# DECODER0_IMG_VIDEO_BUS4_MMU register map
Vendor: Texas Instruments
Peripheral module from a debugger description file (folder J7ES).
Registers are 32-bit, read-write, reset 0x0 unless marked. A register's access mark holds for its fields unless they carry their own. Offsets are as the file gives them; lines under a group give offsets from that group; [hi:lo] are bit positions; {n}, {i} and the like mark numbered series; 'fields as' and 'values as' point back to an identical list; <NAME> marks a mode.

## DECODER0_IMG_VIDEO_BUS4_MMU
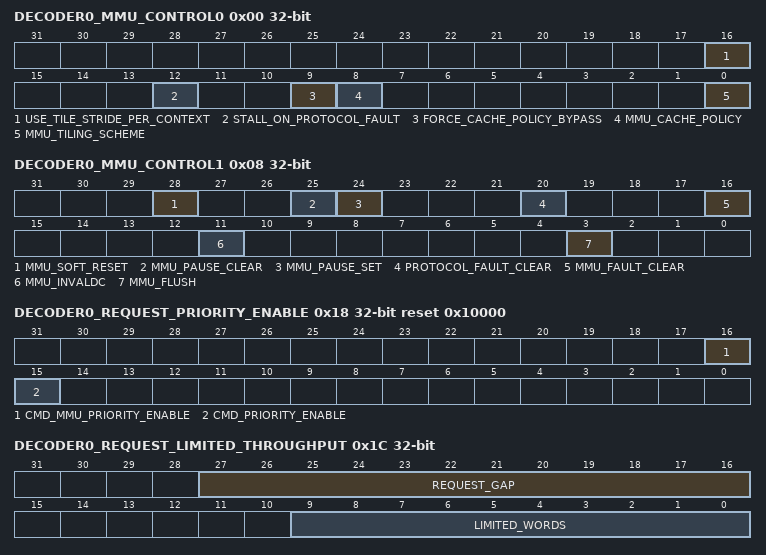
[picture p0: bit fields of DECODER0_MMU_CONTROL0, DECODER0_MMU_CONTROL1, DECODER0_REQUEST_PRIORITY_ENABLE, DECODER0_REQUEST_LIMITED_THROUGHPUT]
0x00 DECODER0_MMU_CONTROL0
  [16] USE_TILE_STRIDE_PER_CONTEXT
  [12] STALL_ON_PROTOCOL_FAULT — Debug only:Setting this bit to '1' causes any requestor with a protocol fault to stall
  [9] FORCE_CACHE_POLICY_BYPASS — Setting this bit to '1' causes all requests to external memory to have a cache policy of 0 [bypass], setting this bit to '0' passes internal cache policy to external interface
  [8] MMU_CACHE_POLICY
  [0] MMU_TILING_SCHEME — This bit controls the tiling scheme described in MMU Address Tiling section
0x08 DECODER0_MMU_CONTROL1
  [28] MMU_SOFT_RESET — Writing '1' to this bit causes all currently active or new memory requests to be discarded, so a reset of all active requestors is likely to also be required.
  [25] MMU_PAUSE_CLEAR — Writing '1' to this bit clears the pause bit, and allows new memory requests to resume.
  [24] MMU_PAUSE_SET — Writing '1' to this bit causes all new memory requests to pause [requests further down the pipeline will be allowed to complete].
  [20] PROTOCOL_FAULT_CLEAR — Writing '1' to this bit clears all bus protocol fault flags.
  [16] MMU_FAULT_CLEAR — Writing '1' to this bit clears MMU fault [either page fault or read/write fault].
  [11] MMU_INVALDC — For each 'dir_base_addr' used, writing '1' triggers invalidation[/flushing] of both the directory cache and page table cache for that 'dir_base_addr' [cached results for different 'dir_base_addr' can be invalidated/flushed independently].
  [3] MMU_FLUSH — For each 'dir_base_addr' used, writing '1' triggers a flush of the Page Table cache and registered results for that 'dir_base_addr' [cached results for different 'dir_base_addr' can be flushed independently].
0x10 DECODER0_MMU_BANK_INDEX
  [31:30] MMU_BANK_INDEX — Specify which directory base address to use for 'group override' input n [If GROUP_OVERRIDE_SIZE is 0, this register is not used, otherwise there are '2 to the power GROUP_OVERRIDE_SIZE' entries supported in this register
0x14 DECODER0_EXT_REQUEST_PRIORITY_ENABLE
  [31] EXT_CMD_PRIORITY_ENABLE — This register is only used if there are more than 16 requestors, in which case it defines the enable for requestors 16 to 47.
0x18 DECODER0_REQUEST_PRIORITY_ENABLE reset 0x10000
  [16] CMD_MMU_PRIORITY_ENABLE — MMU requests [Directory Table and Page Table reads] should normally be considered a priority on the bus infrastructure.
  [15] CMD_PRIORITY_ENABLE — Each requestor can generate a command priority signal to indicate the request should be treated as a priority in the external bus infrastructure [MMU requests are always considered to be a priority].
0x1C DECODER0_REQUEST_LIMITED_THROUGHPUT — This register controls the memory bus stalling behaviour which occurs when the 'mem_limited_throughput' input is set. The 'mem_limited_throughput' input is set by the bus fabric to indicate that the bus infrastructure is becoming saturated and that the bandwidth consumed by lower priority requests should be limited. When the 'mem_limited_throughput' input is set, for 'REQUEST_GAP' cycles all command requests into the MMU will be stalled (any requests already inside the MMU are allowed to continue as normal). Once the request gap is complete, 'LIMITED_WORDS' commands will be allowed into the MMU. When the 'mem_limited_throughput' input is cleared the counters are disabled (set to zero) and all requests proceed without limit. High priority requests (as defined by the CMD_PRIORITY_ENABLE register) are not stalled and pass unheeded. When either REQUEST_GAP or LIMITED_WORDS is set to zero the counters are disabled (set to zero) and all memory requests pass unheeded. N.B. LIMITED_WORDS threshold applies to commands, where there are typically 4 words transferred per command, so the bandwidth stalling ratio is typically closer to LIMTED_WORDS*4:REQUEST_GAP
  [27:16] REQUEST_GAP — Number of cycles all command requests are stalled for due to 'mem_limited_throughput' being set
  [9:0] LIMITED_WORDS — Number of commands which can be issued before all requests are stalled for 'REQUEST_GAP' cycles due to 'mem_limited_throughput' being set
{0x20+4i} DECODER0_MMU_DIR_BASE_ADDR_{i:02} (i=0..3)
  [31:0] MMU_DIR_BASE_ADDR — Base address in physical memory for MMU Directory n Entries.
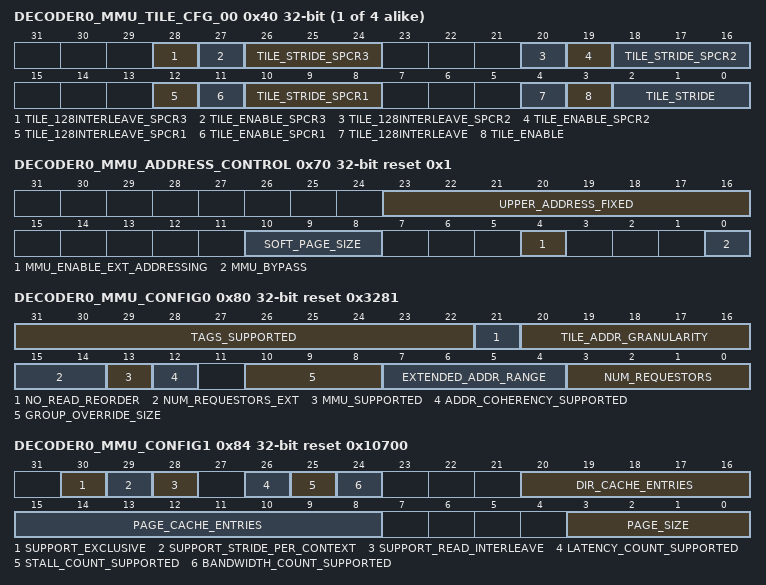
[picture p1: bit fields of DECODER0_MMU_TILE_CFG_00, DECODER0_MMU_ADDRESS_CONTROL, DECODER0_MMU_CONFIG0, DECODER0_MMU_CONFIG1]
{0x40+4i} DECODER0_MMU_TILE_CFG_{i:02} (i=0..3) — If USE_TILE_STRIDE_PER_CONTEXT is low, only the bottom byte of the register is used, and each of the four registers applies to the four regions defined by the corresponding MIN and MAX tile address ranges.If USE_TILE_STRIDE_PER_CONTEXT is high, the four bytes in a register applies to the four regions defined by the corresponding MIN and MAX tile address ranges. Then each of the four registers apply to four different contexts, where each context can use a different stride, but the MIN to MAX address range defining each region is common to all contexts (where context is the 2-bit index selected from the register).
  [28] TILE_128INTERLEAVE_SPCR3
  [27] TILE_ENABLE_SPCR3
  [26:24] TILE_STRIDE_SPCR3 — Defines the X Tile Stride for the memory address range [stride is 2 to the power of [9+tile_stride+tiling_scheme]]
  [20] TILE_128INTERLEAVE_SPCR2
  [19] TILE_ENABLE_SPCR2
  [18:16] TILE_STRIDE_SPCR2 — Defines the X Tile Stride for the memory address range [stride is 2 to the power of [9+tile_stride+tiling_scheme]]
  [12] TILE_128INTERLEAVE_SPCR1
  [11] TILE_ENABLE_SPCR1
  [10:8] TILE_STRIDE_SPCR1 — Defines the X Tile Stride for the memory address range [stride is 2 to the power of [9+tile_stride+tiling_scheme]]
  [4] TILE_128INTERLEAVE
  [3] TILE_ENABLE
  [2:0] TILE_STRIDE — Defines the X Tile Stride for the memory address range [stride is 2 to the power of [9+tile_stride+tiling_scheme]]
{0x50+4i} DECODER0_MMU_TILE_MIN_ADDR_{i:02} (i=0..3)
  [31:0] TILE_MIN_ADDR — Defines the minimum address for tiling range, in terms of the virtual address MSB's i.e.
{0x60+4i} DECODER0_MMU_TILE_MAX_ADDR_{i:02} (i=0..3)
  [31:0] TILE_MAX_ADDR — Defines the maximum address for tiling range, in terms of the virtual address MSB's i.e.
0x70 DECODER0_MMU_ADDRESS_CONTROL reset 0x1
  [23:16] UPPER_ADDRESS_FIXED — If 'EXTENDED_ADDR_RANGE' is &gt; 0, and MMU is used in bypass mode or MMU_ENABLE_EXT_ADDRESSING = '0', EXTENDED_ADDR_RANGE bits from this field will be used to define the state of the upper physical address bits [for all memory requests]
  [10:8] SOFT_PAGE_SIZE — This field selects MMU page size at run time [if this field is less than the minimum hardware configuration for PAGE_SIZE from
  [4] MMU_ENABLE_EXT_ADDRESSING
  [0] MMU_BYPASS
0x80 DECODER0_MMU_CONFIG0 ro reset 0x3281
  [31:22] TAGS_SUPPORTED — Number of outstanding bursts supported
  [21] NO_READ_REORDER — If this field is set, it indicates there is no read data re-ordering buffer [all requestors must accept read response out of order]
  [20:16] TILE_ADDR_GRANULARITY — This field indicates the granularity of the tile address range [where virtual address range is matched from
  [15:14] NUM_REQUESTORS_EXT — In MMU version 4.2 onwards, NUM_REQUESTORS_EXT*16 + NUM_REQUESTORS indicates the number of requestors the core has been configured for [before version 4.2 this field was always 0]
  [13] MMU_SUPPORTED — This field indicates if MMU page table mapping is supported [N.B.
  [12] ADDR_COHERENCY_SUPPORTED — This field indicates if address coherency checking is supported [if it is not supported requestors need to use another mechanism to gurantee reads and writes to the same address don't occur out of order]
  [10:8] GROUP_OVERRIDE_SIZE — If this field is 0, only 1 directory base address is supported [MMU_DIR_BASE_ADDR0].
  [7:4] EXTENDED_ADDR_RANGE — This field indicates the number of extended address bits [above 32] that the external memory interface uses
  [3:0] NUM_REQUESTORS — Before MMU version 4.2, this field indicates the number of requestors the core has been configured for [between 1 and 15, or a value of
0x84 DECODER0_MMU_CONFIG1 ro reset 0x10700
  [30] SUPPORT_EXCLUSIVE — Logic included to support exclusive transactions [for doing read-modify-write without another master modifying the value]
  [29] SUPPORT_STRIDE_PER_CONTEXT — Logic included to support separate tile stride per context
  [28] SUPPORT_READ_INTERLEAVE — Logic included to support interleaved read responses [violates Bus4 protocol but may occur when Bus4 to AXI bridge is used]
  [26] LATENCY_COUNT_SUPPORTED — Latency counts included
  [25] STALL_COUNT_SUPPORTED — Stall counts included
  [24] BANDWIDTH_COUNT_SUPPORTED — Bandwidth counts included
  [20:16] DIR_CACHE_ENTRIES — DIR_CACHE_ENTRIES * 128 defines the number of Directory Table entries which can be cached
  [15:8] PAGE_CACHE_ENTRIES — PAGE_CACHE_ENTRIES * 128 defines the number of Page Table entries which can be cached
  [3:0] PAGE_SIZE — Log2 MMU page size minus 12 [4kbyte page = 0, 16kbyte page = 2]
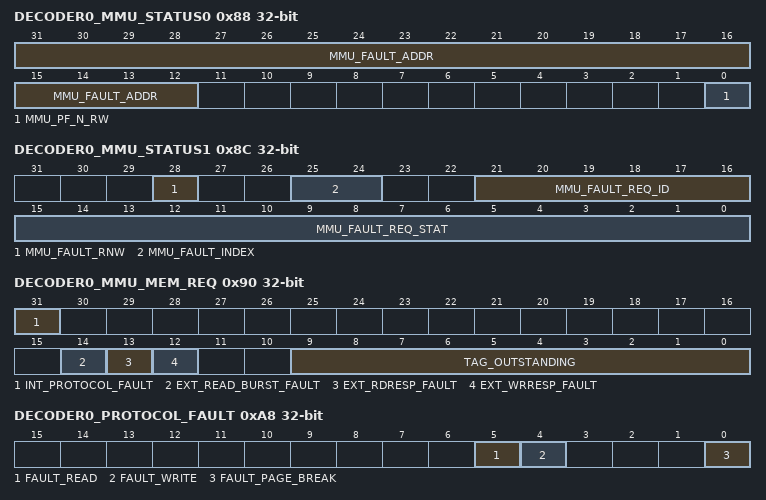
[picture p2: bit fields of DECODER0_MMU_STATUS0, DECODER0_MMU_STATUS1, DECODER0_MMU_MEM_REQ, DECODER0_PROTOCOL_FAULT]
0x88 DECODER0_MMU_STATUS0 ro
  [31:12] MMU_FAULT_ADDR — Page-aligned virtual address causing page fault
  [0] MMU_PF_N_RW — Indicates whether the current fault is a page fault [when high] or R/W protection fault [when low]
0x8C DECODER0_MMU_STATUS1 ro
  [28] MMU_FAULT_RNW — Indicates if a read or write operation caused the current fault
  [25:24] MMU_FAULT_INDEX — Indicates the directory cache index of the current fault
  [21:16] MMU_FAULT_REQ_ID — Indicates the requestor ID of the request causing the current page fault
  [15:0] MMU_FAULT_REQ_STAT
0x90 DECODER0_MMU_MEM_REQ ro
  [31] INT_PROTOCOL_FAULT — When set, indicates the corresponding requestor had a bus protocol fault [excludes MMU requests]
  [14] EXT_READ_BURST_FAULT — When set, indicates the external interface returned a read burst for a tag which didn't contain the expected number of words
  [13] EXT_RDRESP_FAULT — When set, indicates the external interface returned a read response for a tag which wasn't outstanding [may occur after reset]
  [12] EXT_WRRESP_FAULT — When set, indicates the external interface returned a write response for a tag which wasn't outstanding [may occur after reset]
  [9:0] TAG_OUTSTANDING — Number of outstanding burst requests [TAGS which have been allocated but not yet freed, includes reads which have been returned but are still in the read re-order buffer]
0x94 DECODER0_MMU_MEM_EXT_OUTSTANDING ro
  [15:0] READ_WORDS_OUTSTANDING — Number of outstanding read words [in which read commands have been sent to the external interface, but the corresponding words haven't been received yet, counted in 'external data bus width' words]
0xA0 DECODER0_MMU_FAULT_SELECT
  [3:0] MMU_FAULT_SELECT — The core can be configured to include protocol checkers on the input requestors, this field selects which interface is read from the
0xA8 DECODER0_PROTOCOL_FAULT ro
  [5] FAULT_READ — For requestor interface, indicates a read command on a requestor configured for write only
  [4] FAULT_WRITE — For requestor interface, indicates a write command on a requestor configured for read only
  [0] FAULT_PAGE_BREAK — The command crossed a page in the middle of a burst
0x100 DECODER0_TOTAL_READ_REQ ro — If .BANDWIDTH_COUNT_SUPPORTED is 0, this register will be fixed at 0.
  [31:0] TOTAL_READ_REQ — Debug only: Total number of bytes read
0x104 DECODER0_TOTAL_WRITE_REQ ro — If .BANDWIDTH_COUNT_SUPPORTED is 0, this register will be fixed at 0.
  [31:0] TOTAL_WRITE_REQ — Debug only: Total number of bytes written
0x108 DECODER0_READS_LESS_64_REQ ro — If .BANDWIDTH_COUNT_SUPPORTED is 0, this register will be fixed at 0.
  [31:0] READS_LESS_64_REQ — Debug only: Total number of bytes read using a burst size less than 64 bytes
0x10C DECODER0_WRITES_LESS_64_REQ ro — If .BANDWIDTH_COUNT_SUPPORTED is 0, this register will be fixed at 0.
  [31:0] WRITES_LESS_64_REQ — Debug only: Total number of bytes written using a burst size less than 64 bytes
0x120 DECODER0_EXT_CMD_STALL ro — If .STALL_COUNT_SUPPORTED is 0, this register will be fixed at 0.
  [31:0] EXT_CMD_STALL — Debug only: Number of cycles in which command out of Page Table lookup stalled by external interface
0x124 DECODER0_WRITE_REQ_STALL ro — If .STALL_COUNT_SUPPORTED is 0, this register will be fixed at 0.
  [31:0] WRITE_REQ_STALL — Debug only: Number of cycles in which command out of Page Table lookup stalled by write request FIFO
0x128 DECODER0_MMU_MISS_STALL ro — If .STALL_COUNT_SUPPORTED is 0, this register will be fixed at 0.
  [31:0] MMU_MISS_STALL — Debug only: Number of cycles in which command is stalled because MMU cache miss buffer is full
0x12C DECODER0_ADDRESS_STALL ro — If .STALL_COUNT_SUPPORTED is 0, this register will be fixed at 0.
  [31:0] ADDRESS_STALL — Debug only: Number of cycles in which command is stalled because Address coherency buffer is full
0x130 DECODER0_TAG_STALL ro — If .STALL_COUNT_SUPPORTED is 0, this register will be fixed at 0.
  [31:0] TAG_STALL — Debug only: Number of cycles in which command is stalled because no free TAGs to allocate
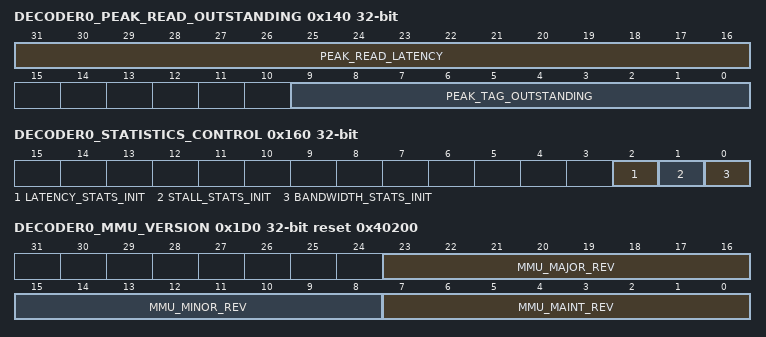
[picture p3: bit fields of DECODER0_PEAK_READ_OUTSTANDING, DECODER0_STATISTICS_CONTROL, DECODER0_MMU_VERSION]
0x140 DECODER0_PEAK_READ_OUTSTANDING ro — If .LATENCY_COUNT_SUPPORTED is 0, this register will be fixed at 0.
  [31:16] PEAK_READ_LATENCY — Debug only: Peak read latency detected [number of cycles a read tag remains outstanding]
  [9:0] PEAK_TAG_OUTSTANDING — Debug only: Largest value on TAG_OUTSTANDING since last initialisation
0x144 DECODER0_AVERAGE_READ_LATENCY ro — If .LATENCY_COUNT_SUPPORTED is 0, this register will be fixed at 0.
  [31:0] AVERAGE_READ_LATENCY — Uses an IIR function on read latency, where the 16 MSBits are the same resolution as PEAK_READ_LATENCY
0x160 DECODER0_STATISTICS_CONTROL
  [2] LATENCY_STATS_INIT — Writing '1' resets the latency statistics [this bit automatically clears to '0']
  [1] STALL_STATS_INIT — Writing '1' resets the stall count statistics [this bit automatically clears to '0']
  [0] BANDWIDTH_STATS_INIT — Writing '1' resets the bandwidth statistics [this bit automatically clears to '0']
0x1D0 DECODER0_MMU_VERSION ro reset 0x40200
  [23:16] MMU_MAJOR_REV — MMU Major Revision
  [15:8] MMU_MINOR_REV — MMU Minor Revision
  [7:0] MMU_MAINT_REV — MMU Maintenance Revision
